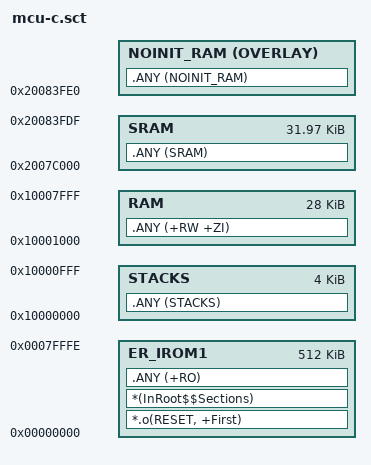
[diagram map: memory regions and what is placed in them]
; *************************************************************
; *** Scatter-Loading Description File generated by uVision ***
; *************************************************************

LR_IROM1 0x00000000 0x00080000  {    ; load region size_region
  ER_IROM1 0x00000000 0x0007FFFF  {  ; load address = execution address
   *.o(RESET, +First)
   *(InRoot$$Sections)
   .ANY (+RO)
  }
  STACKS 0x10000000 0x1000  {  ; RW data
   .ANY (STACKS)
  }
  RAM 0x10001000 0x00007000  {  ; RW data
   .ANY (+RW +ZI)
  }
  SRAM 0x2007c000 0x00007fe0  {  ; RW data
   .ANY (SRAM)
  }
  NOINIT_RAM 0x20083fe0 OVERLAY {  ; RW data
   .ANY (NOINIT_RAM)
  }
}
